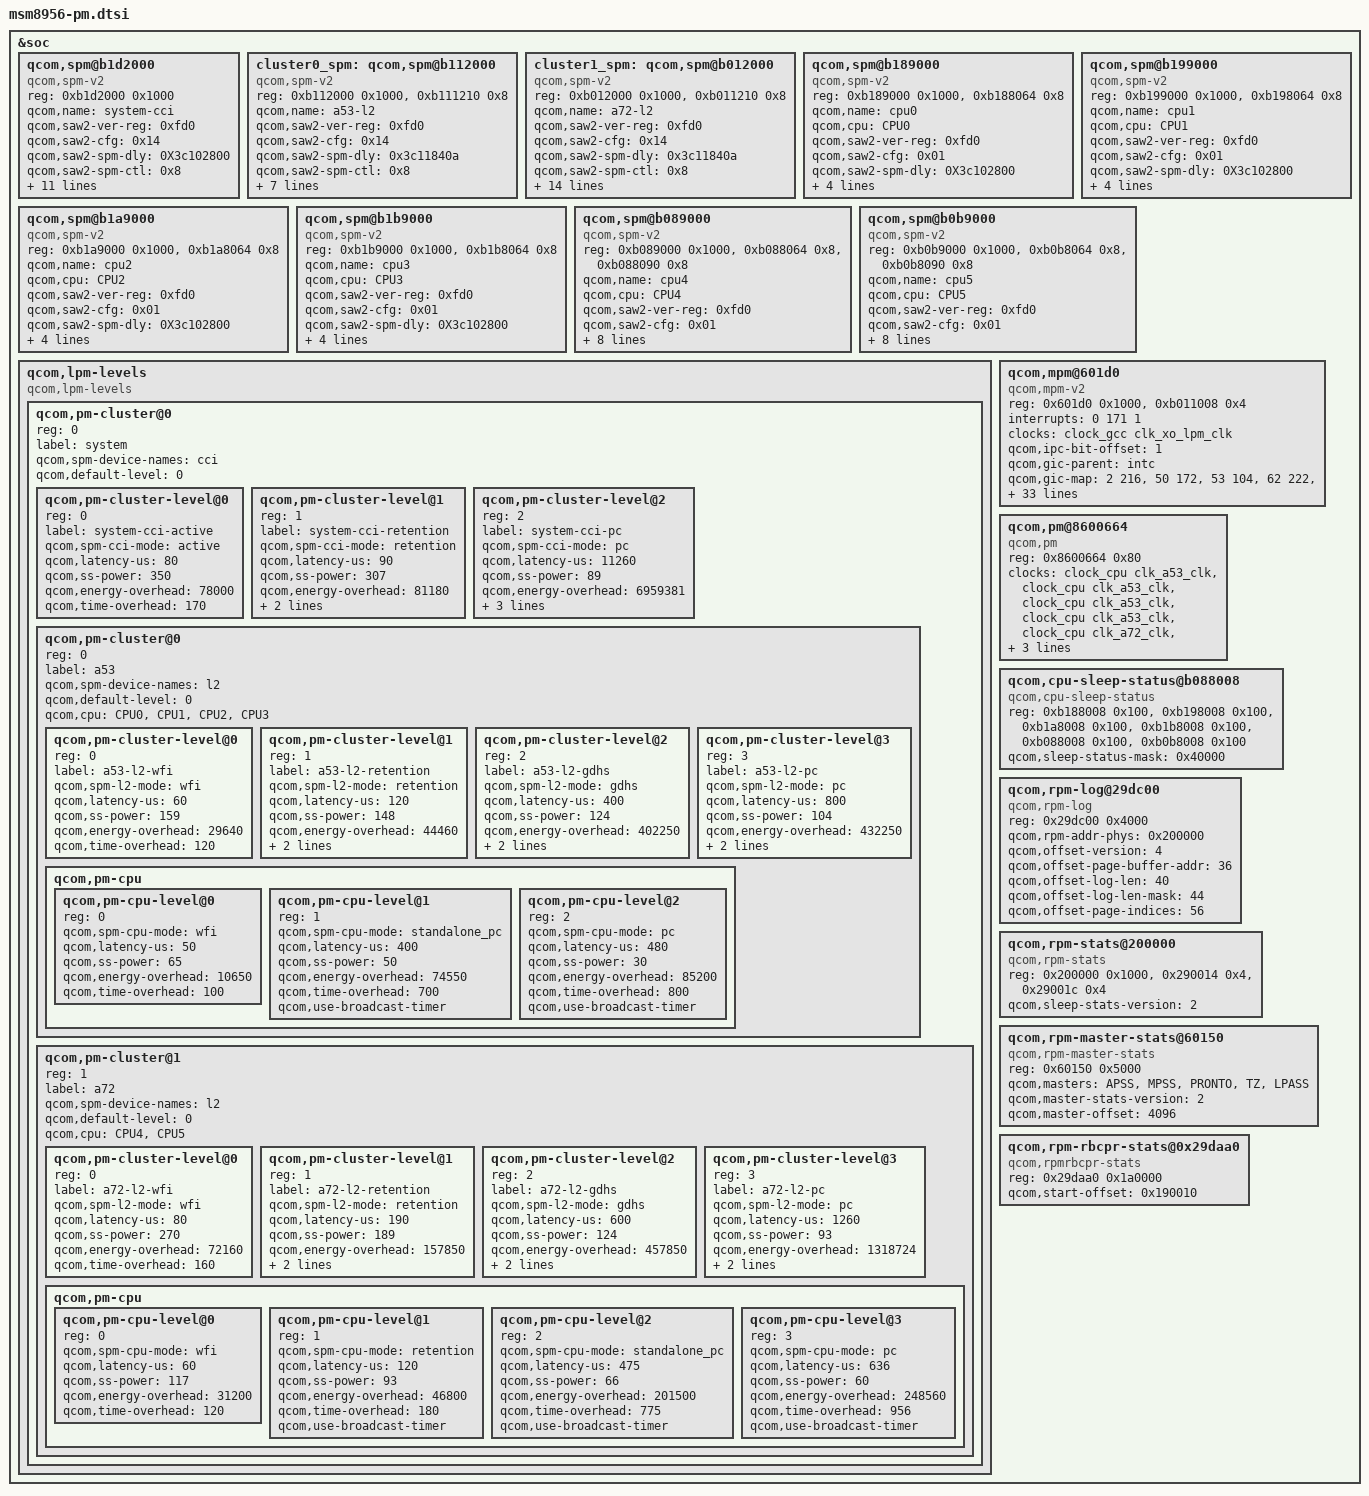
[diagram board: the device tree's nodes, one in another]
/* Copyright (c) 2015, The Linux Foundation. All rights reserved.
 *
 * This program is free software; you can redistribute it and/or modify
 * it under the terms of the GNU General Public License version 2 and
 * only version 2 as published by the Free Software Foundation.
 *
 * This program is distributed in the hope that it will be useful,
 * but WITHOUT ANY WARRANTY; without even the implied warranty of
 * MERCHANTABILITY or FITNESS FOR A PARTICULAR PURPOSE.  See the
 * GNU General Public License for more details.
 */

&soc {
	qcom,spm@b1d2000 {
		compatible = "qcom,spm-v2";
		#address-cells = <1>;
		#size-cells = <1>;
		reg = <0xb1d2000 0x1000>;
		qcom,name = "system-cci"; /* CCI SAW */
		qcom,saw2-ver-reg = <0xfd0>;
		qcom,saw2-cfg = <0x14>;
		qcom,saw2-spm-dly = <0X3c102800>;
		qcom,saw2-spm-ctl = <0x8>;
		qcom,cpu-vctl-list = <&CPU0 &CPU1 &CPU2 &CPU3>;
		qcom,vctl-timeout-us = <50>;
		qcom,vctl-port = <0x0>;
		qcom,phase-port = <0x1>;
		qcom,supports-rpm-hs;
		qcom,saw2-pmic-data0 = <0x03030080>; /* VDD_APC0 on */
		qcom,saw2-pmic-data1 = <0x00030000>; /* VDD_APC0 off  */
		qcom,pfm-port = <0x2>;
		qcom,saw2-spm-cmd-ret = [00 03 00 0f];
		qcom,saw2-spm-cmd-pc = [00 60 50 11 03 70 01 50 02 62 72 0f];
	};

	cluster0_spm: qcom,spm@b112000 {
		compatible = "qcom,spm-v2";
		#address-cells = <1>;
		#size-cells = <1>;
		reg = <0xb112000 0x1000>,
		    <0xb111210 0x8>; /* SPM_QCHANNEL_CFG */
		qcom,name = "a53-l2"; /* A53 L2 SAW */
		qcom,saw2-ver-reg = <0xfd0>;
		qcom,saw2-cfg = <0x14>;
		qcom,saw2-spm-dly = <0x3c11840a>;
		qcom,saw2-spm-ctl = <0x8>;
		qcom,saw2-spm-cmd-wfi = [03 0f]; /* Removed clk gating cmds */
		qcom,saw2-spm-cmd-ret = [b0 7b 48 26 6b b0 03 2f 1b b0 7b 26 6b
			58 58 48 b0 0f];
		qcom,saw2-spm-cmd-gdhs = [b0 7b 00 50 32 48 26 6b c0 42 5b f0
			b0 03 1f 1b b0 7b 46 2b 3b c0 22 6b 58 58 48 02 32 52 f0
			b0 0f];
		qcom,saw2-spm-cmd-pc = [b0 7b 00 50 32 48 26 6b 16 6b c0 42 5b
			b0 03 1f 1b b0 7b 46 2b 3b c0 12 6b 22 6b 58 58 48 02 32
			50 b0 0f];
	};

	cluster1_spm: qcom,spm@b012000 {
		compatible = "qcom,spm-v2";
		#address-cells = <1>;
		#size-cells = <1>;
		reg = <0xb012000 0x1000>,
		    <0xb011210 0x8>; /* SPM_QCHANNEL_CFG */
		qcom,name = "a72-l2"; /* A5x L2 SAW */
		qcom,saw2-ver-reg = <0xfd0>;
		qcom,saw2-cfg = <0x14>;
		qcom,saw2-spm-dly = <0x3c11840a>;
		qcom,saw2-spm-ctl = <0x8>;
		qcom,cpu-vctl-list = <&CPU4 &CPU5>;
		qcom,vctl-timeout-us = <50>;
		qcom,vctl-port = <0x0>;
		qcom,phase-port = <0x1>;
		qcom,saw2-pmic-data0 = <0x03030080>; /* VDD_APC1 on */
		qcom,saw2-pmic-data1 = <0x00030000>; /* VDD_APC1 off  */
		qcom,pfm-port = <0x2>;
		qcom,saw2-spm-cmd-wfi = [03 0f];
		qcom,saw2-spm-cmd-ret = [b0 7b 48 26 6b b0 03 2f 1b b0 7b 26 6b
			58 58 48 b0 0f];
		qcom,saw2-spm-cmd-gdhs = [b0 7b 00 50 32 48 26 6b c0 e2 42 5b f0
			b0 03 1f 1b b0 7b 46 2b e2 3b c0 22 6b 58 58 48 02 32 52
			f0 b0 0f];
		qcom,saw2-spm-cmd-pc = [b0 7b 00 50 32 48 26 6b 16 6b c0 e2 42 5b
			b0 18 11 03 01 18 1f 1b b0 7b 46 2b e2 3b c0 12 6b 22 6b
			58 58 48 02 32 50 b0 0f];
	};

	qcom,spm@b189000 {
		compatible = "qcom,spm-v2";
		#address-cells = <1>;
		#size-cells = <1>;
		reg = <0xb189000 0x1000>,
			<0xb188064 0x8>; /* SPM_QCHANNEL_CFG */
		qcom,name = "cpu0";
		qcom,cpu = <&CPU0>;
		qcom,saw2-ver-reg = <0xfd0>;
		qcom,saw2-cfg = <0x01>;
		qcom,saw2-spm-dly = <0X3c102800>;
		qcom,saw2-spm-ctl = <0x8>;
		qcom,saw2-spm-cmd-wfi = [03 0f];
		qcom,saw2-spm-cmd-pc = [50 2b 30 40 00 c0 14 3b 24 3b 80 92 1b
			50 03 76 76 0b 50 2b 92 1b 80 24 3b 14 3b 70 70 c0 04 46
			30 50 0f];
	};

	qcom,spm@b199000 {
		compatible = "qcom,spm-v2";
		#address-cells = <1>;
		#size-cells = <1>;
		reg = <0xb199000 0x1000>,
			<0xb198064 0x8>; /* SPM_QCHANNEL_CFG */
		qcom,name = "cpu1";
		qcom,cpu = <&CPU1>;
		qcom,saw2-ver-reg = <0xfd0>;
		qcom,saw2-cfg = <0x01>;
		qcom,saw2-spm-dly = <0X3c102800>;
		qcom,saw2-spm-ctl = <0x8>;
		qcom,saw2-spm-cmd-wfi = [03 0f];
		qcom,saw2-spm-cmd-pc = [50 2b 30 40 00 c0 14 3b 24 3b 80 92 1b
			50 03 76 76 0b 50 2b 92 1b 80 24 3b 14 3b 70 70 c0 04 46
			30 50 0f];
	};

	qcom,spm@b1a9000 {
		compatible = "qcom,spm-v2";
		#address-cells = <1>;
		#size-cells = <1>;
		reg = <0xb1a9000 0x1000>,
		    <0xb1a8064 0x8>; /* SPM_QCHANNEL_CFG */
		qcom,name = "cpu2";
		qcom,cpu = <&CPU2>;
		qcom,saw2-ver-reg = <0xfd0>;
		qcom,saw2-cfg = <0x01>;
		qcom,saw2-spm-dly = <0X3c102800>;
		qcom,saw2-spm-ctl = <0x8>;
		qcom,saw2-spm-cmd-wfi = [03 0f];
		qcom,saw2-spm-cmd-pc = [50 2b 30 40 00 c0 14 3b 24 3b 80 92 1b
			50 03 76 76 0b 50 2b 92 1b 80 24 3b 14 3b 70 70 c0 04 46
			30 50 0f];
	};

	qcom,spm@b1b9000 {
		compatible = "qcom,spm-v2";
		#address-cells = <1>;
		#size-cells = <1>;
		reg = <0xb1b9000 0x1000>,
		    <0xb1b8064 0x8>; /* SPM_QCHANNEL_CFG */
		qcom,name = "cpu3";
		qcom,cpu = <&CPU3>;
		qcom,saw2-ver-reg = <0xfd0>;
		qcom,saw2-cfg = <0x01>;
		qcom,saw2-spm-dly = <0X3c102800>;
		qcom,saw2-spm-ctl = <0x8>;
		qcom,saw2-spm-cmd-wfi = [03 0f];
		qcom,saw2-spm-cmd-pc = [50 2b 30 40 00 c0 14 3b 24 3b 80 92 1b
			50 03 76 76 0b 50 2b 92 1b 80 24 3b 14 3b 70 70 c0 04 46
			30 50 0f];
	};

	qcom,spm@b089000 {
		compatible = "qcom,spm-v2";
		#address-cells = <1>;
		#size-cells = <1>;
		reg = <0xb089000 0x1000>,
		    <0xb088064 0x8>, /* SPM_QCHANNEL_CFG */
		    <0xb088090 0x8>; /* QCHANNEL_STANDBY_FSM_CTL */
		qcom,name = "cpu4";
		qcom,cpu = <&CPU4>;
		qcom,saw2-ver-reg = <0xfd0>;
		qcom,saw2-cfg = <0x01>;
		qcom,saw2-spm-dly = <0X3c102800>;
		qcom,saw2-spm-ctl = <0x8>;
		qcom,use-c1-exit-fsm-for-wfi;
		qcom,saw2-spm-cmd-wfi = [03 0f];
		qcom,saw2-spm-cmd-ret = [40 50 2b 00 c0 14 3b b6 e8 98 a0 1b 50
			03 2f 0b 50 2b 92 1b e2 1b b0 a0 14 3b 70 70 c0 00 50 40
			0f];
		qcom,saw2-spm-cmd-pc = [50 2b 30 40 00 c0 14 3b 24 3b 80 e2 92
			1b 50 03 76 76 0b 50 2b 92 e2 1b 80 24 3b 14 3b 70 70
			c0 04 46 30 50 0f];
	};

	qcom,spm@b0b9000 {
		compatible = "qcom,spm-v2";
		#address-cells = <1>;
		#size-cells = <1>;
		reg = <0xb0b9000 0x1000>,
		    <0xb0b8064 0x8>, /* SPM_QCHANNEL_CFG */
		    <0xb0b8090 0x8>; /* QCHANNEL_STANDBY_FSM_CTL */
		qcom,name = "cpu5";
		qcom,cpu = <&CPU5>;
		qcom,saw2-ver-reg = <0xfd0>;
		qcom,saw2-cfg = <0x01>;
		qcom,saw2-spm-dly = <0X3c102800>;
		qcom,saw2-spm-ctl = <0x8>;
		qcom,use-c1-exit-fsm-for-wfi;
		qcom,saw2-spm-cmd-wfi = [03 0f];
		qcom,saw2-spm-cmd-ret = [40 50 2b 00 c0 14 3b b6 e8 98 a0 1b 50
			03 2f 0b 50 2b 92 1b e2 1b b0 a0 14 3b 70 70 c0 00 50 40
			0f];
		qcom,saw2-spm-cmd-pc = [50 2b 30 40 00 c0 14 3b 24 3b 80 e2 92
			1b 50 03 76 76 0b 50 2b 92 e2 1b 80 24 3b 14 3b 70 70
			c0 04 46 30 50 0f];
	};

	qcom,lpm-levels {
		compatible = "qcom,lpm-levels";
		#address-cells = <1>;
		#size-cells = <0>;

		qcom,pm-cluster@0 {
			reg = <0>;
			#address-cells = <1>;
			#size-cells = <0>;
			label = "system";
			qcom,spm-device-names = "cci";
			qcom,default-level = <0>;

			qcom,pm-cluster-level@0{
				reg = <0>;
				label = "system-cci-active";
				qcom,spm-cci-mode = "active";
				qcom,latency-us = <80>;
				qcom,ss-power = <350>;
				qcom,energy-overhead = <78000>;
				qcom,time-overhead = <170>;
			};

			qcom,pm-cluster-level@1{
				reg = <1>;
				label = "system-cci-retention";
				qcom,spm-cci-mode = "retention";
				qcom,latency-us = <90>;
				qcom,ss-power = <307>;
				qcom,energy-overhead = <81180>;
				qcom,time-overhead = <180>;
				qcom,min-child-idx = <2>;
			};

			qcom,pm-cluster-level@2{
				reg = <2>;
				label = "system-cci-pc";
				qcom,spm-cci-mode = "pc";
				qcom,latency-us = <11260>;
				qcom,ss-power = <89>;
				qcom,energy-overhead = <6959381>;
				qcom,time-overhead = <5431>;
				qcom,min-child-idx = <3>;
				qcom,notify-rpm;
			};

			qcom,pm-cluster@0{
				reg = <0>;
				#address-cells = <1>;
				#size-cells = <0>;
				label = "a53";
				qcom,spm-device-names = "l2";
				qcom,default-level=<0>;
				qcom,cpu = <&CPU0 &CPU1 &CPU2 &CPU3>;

				qcom,pm-cluster-level@0{
					reg = <0>;
					label = "a53-l2-wfi";
					qcom,spm-l2-mode = "wfi";
					qcom,latency-us = <60>;
					qcom,ss-power = <159>;
					qcom,energy-overhead = <29640>;
					qcom,time-overhead = <120>;
				};

				qcom,pm-cluster-level@1{
					reg = <1>;
					label = "a53-l2-retention";
					qcom,spm-l2-mode = "retention";
					qcom,latency-us = <120>;
					qcom,ss-power = <148>;
					qcom,energy-overhead = <44460>;
					qcom,time-overhead = <180>;
					qcom,min-child-idx = <1>;
				};

				qcom,pm-cluster-level@2{
					reg = <2>;
					label = "a53-l2-gdhs";
					qcom,spm-l2-mode = "gdhs";
					qcom,latency-us = <400>;
					qcom,ss-power = <124>;
					qcom,energy-overhead = <402250>;
					qcom,time-overhead = <900>;
					qcom,min-child-idx = <2>;
				};

				qcom,pm-cluster-level@3{
					reg = <3>;
					label = "a53-l2-pc";
					qcom,spm-l2-mode = "pc";
					qcom,latency-us = <800>;
					qcom,ss-power = <104>;
					qcom,energy-overhead = <432250>;
					qcom,time-overhead = <1750>;
					qcom,min-child-idx = <2>;
				};

				qcom,pm-cpu {
					#address-cells = <1>;
					#size-cells = <0>;

					qcom,pm-cpu-level@0 {
						reg = <0>;
						qcom,spm-cpu-mode = "wfi";
						qcom,latency-us = <50>;
						qcom,ss-power = <65>;
						qcom,energy-overhead = <10650>;
						qcom,time-overhead = <100>;
					};

					qcom,pm-cpu-level@1 {
						reg = <1>;
						qcom,spm-cpu-mode = "standalone_pc";
						qcom,latency-us = <400>;
						qcom,ss-power = <50>;
						qcom,energy-overhead = <74550>;
						qcom,time-overhead = <700>;
						qcom,use-broadcast-timer;
					};

					qcom,pm-cpu-level@2 {
						reg = <2>;
						qcom,spm-cpu-mode = "pc";
						qcom,latency-us = <480>;
						qcom,ss-power = <30>;
						qcom,energy-overhead = <85200>;
						qcom,time-overhead = <800>;
						qcom,use-broadcast-timer;
					};
				};
			};

			qcom,pm-cluster@1{
				reg = <1>;
				#address-cells = <1>;
				#size-cells = <0>;
				label = "a72";
				qcom,spm-device-names = "l2";
				qcom,default-level=<0>;
				qcom,cpu = <&CPU4 &CPU5>;

				qcom,pm-cluster-level@0{
					reg = <0>;
					label = "a72-l2-wfi";
					qcom,spm-l2-mode = "wfi";
					qcom,latency-us = <80>;
					qcom,ss-power = <270>;
					qcom,energy-overhead = <72160>;
					qcom,time-overhead = <160>;
				};

				qcom,pm-cluster-level@1{
					reg = <1>;
					label = "a72-l2-retention";
					qcom,spm-l2-mode = "retention";
					qcom,latency-us = <190>;
					qcom,ss-power = <189>;
					qcom,energy-overhead = <157850>;
					qcom,time-overhead = <350>;
					qcom,min-child-idx = <1>;
				};

				qcom,pm-cluster-level@2{
					reg = <2>;
					label = "a72-l2-gdhs";
					qcom,spm-l2-mode = "gdhs";
					qcom,latency-us = <600>;
					qcom,ss-power = <124>;
					qcom,energy-overhead = <457850>;
					qcom,time-overhead = <900>;
					qcom,min-child-idx = <3>;
				};

				qcom,pm-cluster-level@3{
					reg = <3>;
					label = "a72-l2-pc";
					qcom,spm-l2-mode = "pc";
					qcom,latency-us = <1260>;
					qcom,ss-power = <93>;
					qcom,energy-overhead = <1318724>;
					qcom,time-overhead = <2924>;
					qcom,min-child-idx = <3>;
				};

				qcom,pm-cpu {
					#address-cells = <1>;
					#size-cells = <0>;

					qcom,pm-cpu-level@0 {
						reg = <0>;
						qcom,spm-cpu-mode = "wfi";
						qcom,latency-us = <60>;
						qcom,ss-power = <117>;
						qcom,energy-overhead = <31200>;
						qcom,time-overhead = <120>;
					};

					qcom,pm-cpu-level@1 {
						reg = <1>;
						qcom,spm-cpu-mode = "retention";
						qcom,latency-us = <120>;
						qcom,ss-power = <93>;
						qcom,energy-overhead = <46800>;
						qcom,time-overhead = <180>;
						qcom,use-broadcast-timer;
					};


					qcom,pm-cpu-level@2 {
						reg = <2>;
						qcom,spm-cpu-mode = "standalone_pc";
						qcom,latency-us = <475>;
						qcom,ss-power = <66>;
						qcom,energy-overhead = <201500>;
						qcom,time-overhead = <775>;
						qcom,use-broadcast-timer;
					};

					qcom,pm-cpu-level@3 {
						reg = <3>;
						qcom,spm-cpu-mode = "pc";
						qcom,latency-us = <636>;
						qcom,ss-power = <60>;
						qcom,energy-overhead = <248560>;
						qcom,time-overhead = <956>;
						qcom,use-broadcast-timer;
					};
				};
			};
		};

	};

	qcom,mpm@601d0 {
		compatible = "qcom,mpm-v2";
		reg = <0x601d0 0x1000>, /* MSM_RPM_MPM_BASE 4K */
		    <0xb011008 0x4>;
		reg-names = "vmpm", "ipc";
		interrupts = <0 171 1>;
		clocks = <&clock_gcc clk_xo_lpm_clk>;
		clock-names = "xo";

		qcom,ipc-bit-offset = <1>;

		qcom,gic-parent = <&intc>;
		qcom,gic-map = <2 216>, /* tsens_upper_lower_int */
			<50 172>, /* usb1_hs_async_wakeup_irq */
			<53 104>, /* mdss_irq */
			<62 222>, /* ee0_krait_hlos_spmi_periph_irq */
			<0xff 18>,  /* APC_qgicQTmrSecPhysIrptReq */
			<0xff 19>,  /* APC_qgicQTmrNonSecPhysIrptReq */
			<0xff 20>,  /* qgicQTmrVirtIrptReq */
			<0xff 35>,  /* WDT_barkInt */
			<0xff 39>,  /* arch_mem_timer */
			<0xff 40>,  /* qtmr_phy_irq[0] */
			<0xff 47>,  /* rbif_irq[0] */
			<0xff 56>,  /* q6_wdog_expired_irq */
			<0xff 57>,  /* mss_to_apps_irq(0) */
			<0xff 58>,  /* mss_to_apps_irq(1) */
			<0xff 59>,  /* mss_to_apps_irq(2) */
			<0xff 60>,  /* mss_to_apps_irq(3) */
			<0xff 61>,  /* mss_a2_bam_irq */
			<0xff 65>,  /* o_gc_sys_irq[0] */
			<0xff 73>,  /* smmu_intr_bus[1] */
			<0xff 74>,  /* smmu_bus_intr[2] */
			<0xff 75>,  /* smmu_bus_intr[3] */
			<0xff 76>,  /* venus_irq */
			<0xff 78>,  /* smmu_bus_intr[5] */
			<0xff 79>,  /* smmu_bus_intr[6] */
			<0xff 85>,  /* smmu_bus_intr[31] */
			<0xff 86>,  /* smmu_bus_intr[32] */
			<0xff 90>,  /* smmu_bus_intr[33] */
			<0xff 92>,  /* smmu_bus_intr[34] */
			<0xff 93>,  /* smmu_bus_intr[35] */
			<0xff 97>,  /* smmu_bus_intr[10] */
			<0xff 102>, /* smmu_bus_intr[14] */
			<0xff 108>, /* smmu_bus_intr[36] */
			<0xff 109>, /* smmu_bus_intr[37] */
			<0xff 112>, /* smmu_bus_intr[38] */
			<0xff 114>, /* qdsd_intr_out */
			<0xff 129>, /* blsp1_peripheral_irq[4] */
			<0xff 131>, /* qup_irq */
			<0xff 137>, /* smmu_intr_bus[44] */
			<0xff 138>, /* smmu_intr_bus[45] */
			<0xff 140>, /* uart_dm_intr */
			<0xff 142>, /* smmu_bus_intr[47] */
			<0xff 143>, /* smmu_bus_intr[48] */
			<0xff 144>, /* smmu_bus_intr[49] */
			<0xff 145>, /* smmu_bus_intr[50] */
			<0xff 146>, /* smmu_bus_intr[51] */
			<0xff 147>, /* smmu_bus_intr[52] */
			<0xff 148>, /* smmu_bus_intr[53] */
			<0xff 149>, /* smmu_bus_intr[54] */
			<0xff 150>, /* smmu_bus_intr[55] */
			<0xff 151>, /* smmu_bus_intr[56] */
			<0xff 152>, /* smmu_bus_intr[57] */
			<0xff 153>, /* smmu_bus_intr[58] */
			<0xff 155>, /* sdc1_irq(0) */
			<0xff 157>, /* sdc2_irq(0) */
			<0xff 166>, /* usb_hs_irq */
			<0xff 167>, /* usb1_hs_bam_irq */
			<0xff 170>, /* sdc1_pwr_cmd_irq */
			<0xff 173>, /* o_wcss_apss_smd_hi */
			<0xff 174>, /* o_wcss_apss_smd_med */
			<0xff 175>, /* o_wcss_apss_smd_low */
			<0xff 176>, /* o_wcss_apss_smsm_irq */
			<0xff 177>, /* o_wcss_apss_wlan_data_xfer_done */
			<0xff 178>, /* o_wcss_apss_wlan_rx_data_avail */
			<0xff 179>, /* o_wcss_apss_asic_intr */
			<0xff 181>, /* o_wcss_apss_wdog_bite_and_reset_rdy */
			<0xff 188>, /* lpass_irq_out_apcs(0) */
			<0xff 189>, /* lpass_irq_out_apcs(1) */
			<0xff 190>, /* lpass_irq_out_apcs(2) */
			<0xff 191>, /* lpass_irq_out_apcs(3) */
			<0xff 192>, /* lpass_irq_out_apcs(4) */
			<0xff 193>, /* lpass_irq_out_apcs(5) */
			<0xff 194>, /* lpass_irq_out_apcs(6) */
			<0xff 195>, /* lpass_irq_out_apcs(7) */
			<0xff 196>, /* lpass_irq_out_apcs(8) */
			<0xff 197>, /* lpass_irq_out_apcs(9) */
			<0xff 198>, /* coresight-tmc-etr interrupt */
			<0xff 200>, /* rpm_ipc(4) */
			<0xff 201>, /* rpm_ipc(5) */
			<0xff 202>, /* rpm_ipc(6) */
			<0xff 203>, /* rpm_ipc(7) */
			<0xff 204>, /* rpm_ipc(24) */
			<0xff 205>, /* rpm_ipc(25) */
			<0xff 206>, /* rpm_ipc(26) */
			<0xff 207>, /* rpm_ipc(27) */
			<0xff 215>, /* o_bimc_intr[0] */
			<0xff 239>, /* crypto_bam_irq[1]*/
			<0xff 240>, /* summary_irq_kpss */
			<0xff 253>, /* sdc2_pwr_cmd_irq */
			<0xff 260>, /* ipa_irq[0] */
			<0xff 262>, /* ipa_bam_irq[0] */
			<0xff 269>, /* rpm_wdog_expired_irq */
			<0xff 270>, /* blsp1_bam_irq[0] */
			<0xff 272>, /* smmu_intr_bus[17] */
			<0xff 273>, /* smmu_bus_intr[18] */
			<0xff 274>, /* smmu_bus_intr[19] */
			<0xff 275>, /* rpm_ipc(30) */
			<0xff 276>, /* rpm_ipc(31) */
			<0xff 277>, /* smmu_intr_bus[20] */
			<0xff 321>, /* q6ss_irq_out(4) */
			<0xff 322>, /* q6ss_irq_out(5) */
			<0xff 323>, /* q6ss_irq_out(6) */
			<0xff 325>; /* q6ss_wdog_exp_irq */

		qcom,gpio-parent = <&msm_gpio>;
		qcom,gpio-map = <3  100>,
			<5  5>,
			<6  9>,
			<8  106>,
			<9  119>,
			<10  133>,
			<11  135>,
			<12  12>,
			<13  13>,
			<14  138>,
			<15  139>,
			<16  140>,
			<17  21>,
			<18  52>,
			<19  25>,
			<20  141>,
			<21  142>,
			<22  28>,
			<23  144>,
			<24  17>,
			<25  33>,
			<26  56>,
			<27  60>,
			<28  38>,
			<29  107>,
			<30  109>,
			<31  45>,
			<32  67>,
			<33  112>,
			<34  113>,
			<35  114>,
			<36  115>,
			<37  68>,
			<38  118>,
			<39  120>,
			<40  121>,
			<41  102>,
			<50  105>,
			<51  130>,
			<52  65>,
			<53  131>,
			<54  39>,
			<55  41>,
			<56  35>;
	};

	qcom,pm@8600664 {
		compatible = "qcom,pm";
		#address-cells = <1>;
		#size-cells = <1>;
		ranges;
		reg = <0x8600664 0x80>;
		clock-names = "cpu0_clk", "cpu1_clk", "cpu2_clk",
				"cpu3_clk", "cpu4_clk", "cpu5_clk",
				"l2_clk";
		clocks = <&clock_cpu clk_a53_clk>,
			 <&clock_cpu clk_a53_clk>,
			 <&clock_cpu clk_a53_clk>,
			 <&clock_cpu clk_a53_clk>,
			 <&clock_cpu clk_a72_clk>,
			 <&clock_cpu clk_a72_clk>,
			 <&clock_cpu clk_cci_clk>;

		qcom,tz-flushes-cache;

		qcom,no-pll-switch-for-retention;

	};

	qcom,cpu-sleep-status@b088008{
		compatible = "qcom,cpu-sleep-status";
		reg = <0xb188008 0x100>,
			<0xb198008 0x100>,
			<0xb1a8008 0x100>,
			<0xb1b8008 0x100>,
			<0xb088008 0x100>,
			<0xb0b8008 0x100>;
		qcom,sleep-status-mask= <0x40000>;
	};

	qcom,rpm-log@29dc00 {
		compatible = "qcom,rpm-log";
		reg = <0x29dc00 0x4000>;
		qcom,rpm-addr-phys = <0x200000>;
		qcom,offset-version = <4>;
		qcom,offset-page-buffer-addr = <36>;
		qcom,offset-log-len = <40>;
		qcom,offset-log-len-mask = <44>;
		qcom,offset-page-indices = <56>;
	};

	qcom,rpm-stats@200000 {
		compatible = "qcom,rpm-stats";
		reg = <0x200000 0x1000>,
		      <0x290014 0x4>,
		      <0x29001c 0x4>;
		reg-names = "phys_addr_base", "offset_addr", "heap_phys_addrbase";
		qcom,sleep-stats-version = <2>;
	};

	qcom,rpm-master-stats@60150 {
		compatible = "qcom,rpm-master-stats";
		reg = <0x60150 0x5000>;
		qcom,masters = "APSS", "MPSS", "PRONTO", "TZ", "LPASS";
		qcom,master-stats-version = <2>;
		qcom,master-offset = <4096>;
	};

	qcom,rpm-rbcpr-stats@0x29daa0  {
		compatible = "qcom,rpmrbcpr-stats";
		reg = <0x29daa0 0x1a0000>;
		qcom,start-offset = <0x190010>;
	};
};
